# N32H7xx register map
Vendor: Nationstech Ltd.; File version: 1.0
CPU: CM7 r1p1, little endian, MPU, FPU, 4 interrupt priority bits
Registers are 32-bit, read-write, reset 0x0 unless marked. A register's access mark holds for its fields unless they carry their own. Offsets are from the block's base; [hi:lo] are bit positions; {n}, {i} and the like mark numbered series; 'fields as' and 'values as' point back to an identical list.

## SHRTIM1_TIMA — Super high resolution timer: TIMA
Base 0x400D8080
Same registers: SHRTIM2_TIMA 0x400D9080
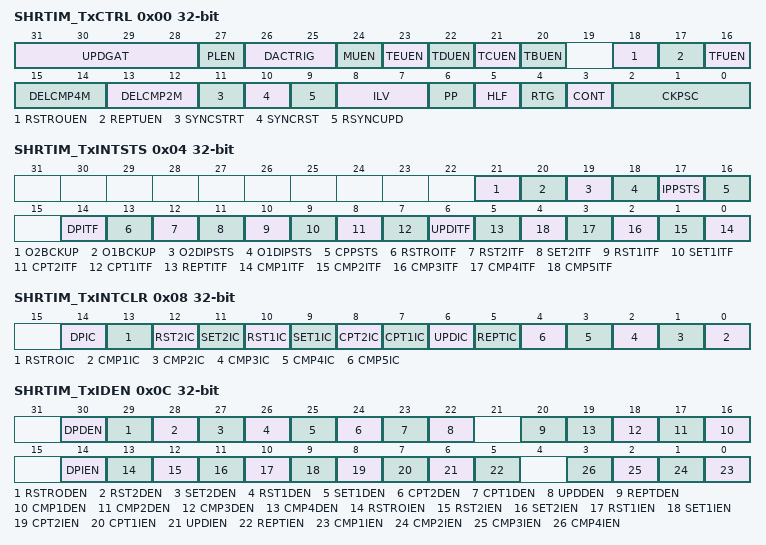
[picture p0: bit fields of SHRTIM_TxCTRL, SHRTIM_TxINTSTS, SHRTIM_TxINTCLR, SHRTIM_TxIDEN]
0x00 SHRTIM_TxCTRL — SHRTIM timer A control register
  [31:28] UPDGAT, [27] PLEN, [26:25] DACTRIG, [24] MUEN, [23] TEUEN, [22] TDUEN, [21] TCUEN, [20] TBUEN, [18] RSTROUEN, [17] REPTUEN, [16] TFUEN, [15:14] DELCMP4M, [13:12] DELCMP2M, [11] SYNCSTRT, [10] SYNCRST, [9] RSYNCUPD, [8:7] ILV, [6] PP, [5] HLF, [4] RTG, [3] CONT, [2:0] CKPSC
0x04 SHRTIM_TxINTSTS ro — SHRTIM timer A interrupt status register
  [21] O2BCKUP, [20] O1BCKUP, [19] O2DIPSTS, [18] O1DIPSTS, [17] IPPSTS, [16] CPPSTS, [14] DPITF, [13] RSTROITF, [12] RST2ITF, [11] SET2ITF, [10] RST1ITF, [9] SET1ITF, [8] CPT2ITF, [7] CPT1ITF, [6] UPDITF, [5] REPTITF, [n-1] CMP{n}ITF (n=1..5)
0x08 SHRTIM_TxINTCLR wo — SHRTIM timer x interrupt clear register
  [14] DPIC, [13] RSTROIC, [12] RST2IC, [11] SET2IC, [10] RST1IC, [9] SET1IC, [8] CPT2IC, [7] CPT1IC, [6] UPDIC, [5] REPTIC, [n-1] CMP{n}IC (n=1..5)
0x0C SHRTIM_TxIDEN — SHRTIM timer x interrupt DMA enable register
  [30] DPDEN, [29] RSTRODEN, [28] RST2DEN, [27] SET2DEN, [26] RST1DEN, [25] SET1DEN, [24] CPT2DEN, [23] CPT1DEN, [22] UPDDEN, [20] REPTDEN, [n+15] CMP{n}DEN (n=1..4), [14] DPIEN, [13] RSTROIEN, [12] RST2IEN, [11] SET2IEN, [10] RST1IEN, [9] SET1IEN, [8] CPT2IEN, [7] CPT1IEN, [6] UPDIEN, [5] REPTIEN, [n-1] CMP{n}IEN (n=1..4)
0x10 SHRTIM_TxCNT — SHRTIM timer x counter register
  [15:0] COUNT
0x14 SHRTIM_TxPRD reset 0xFFDF — SHRTIM timer x period register
  [15:0] PRD
0x18 SHRTIM_TxREPT — SHRTIM timer x repetition register
  [7:0] REPT
0x1C SHRTIM_TxCMP1DAT — SHRTIM timer x compare 1 register
  [15:0] CMP1DAT
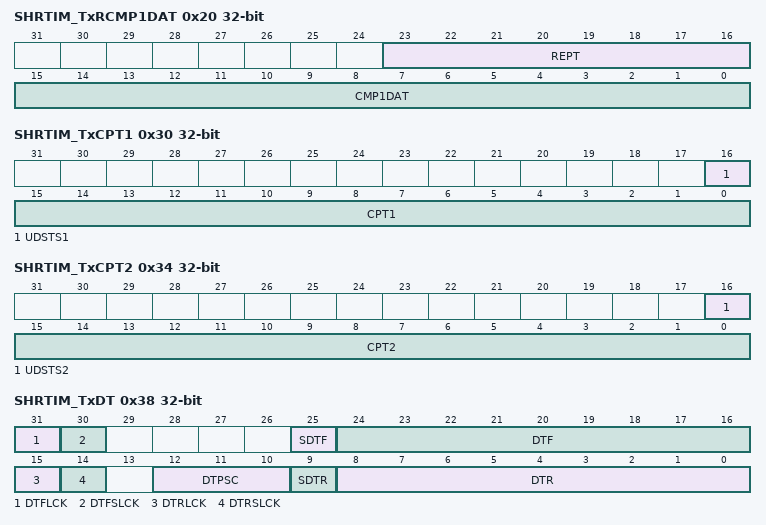
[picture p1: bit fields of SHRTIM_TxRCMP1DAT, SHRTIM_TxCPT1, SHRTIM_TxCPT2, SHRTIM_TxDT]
0x20 SHRTIM_TxRCMP1DAT — SHRTIM timer x compare 1 repetition alias register
  [23:16] REPT, [15:0] CMP1DAT
{0x1C+4i} SHRTIM_TxCMP{i}DAT (i=2..4) — SHRTIM timer x compare {i} register
  [15:0] CMP{i}DAT
0x30 SHRTIM_TxCPT1 — SHRTIM timer x compare 1 register
  [16] UDSTS1, [15:0] CPT1
0x34 SHRTIM_TxCPT2 — SHRTIM timer x compare 2 register
  [16] UDSTS2, [15:0] CPT2
0x38 SHRTIM_TxDT — SHRTIM timer x deadtime register
  [31] DTFLCK, [30] DTFSLCK, [25] SDTF, [24:16] DTF, [15] DTRLCK, [14] DTRSLCK, [12:10] DTPSC, [9] SDTR, [8:0] DTR
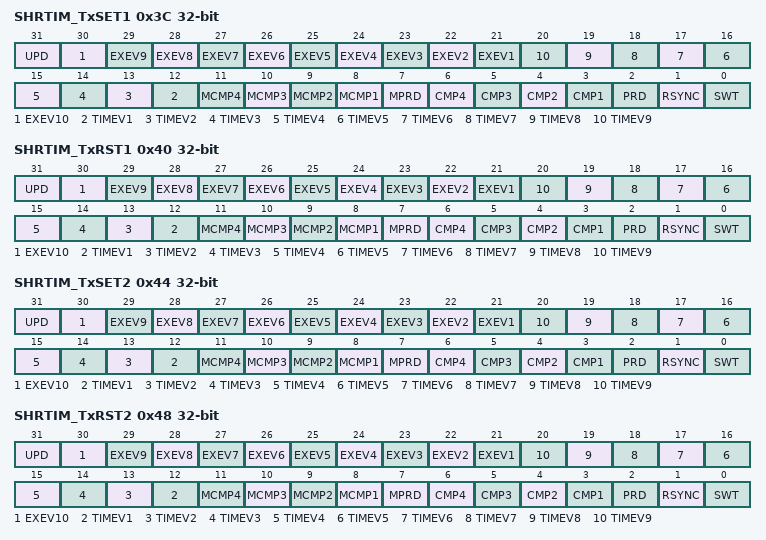
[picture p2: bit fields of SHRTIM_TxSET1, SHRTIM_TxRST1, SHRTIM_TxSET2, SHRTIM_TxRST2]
0x3C SHRTIM_TxSET1 — SHRTIM timer x set register 1
  [31] UPD, [n+20] EXEV{n} (n=1..10), [n+11] TIMEV{n} (n=1..9), [n+7] MCMP{n} (n=1..4), [7] MPRD, [n+2] CMP{n} (n=1..4), [2] PRD, [1] RSYNC, [0] SWT
0x40 SHRTIM_TxRST1 — SHRTIM timer x reset register 1
  fields as SHRTIM_TxSET1
0x44 SHRTIM_TxSET2 — SHRTIM timer x set register 2
  fields as SHRTIM_TxSET1
0x48 SHRTIM_TxRST2 — SHRTIM timer x reset register 2
  fields as SHRTIM_TxSET1
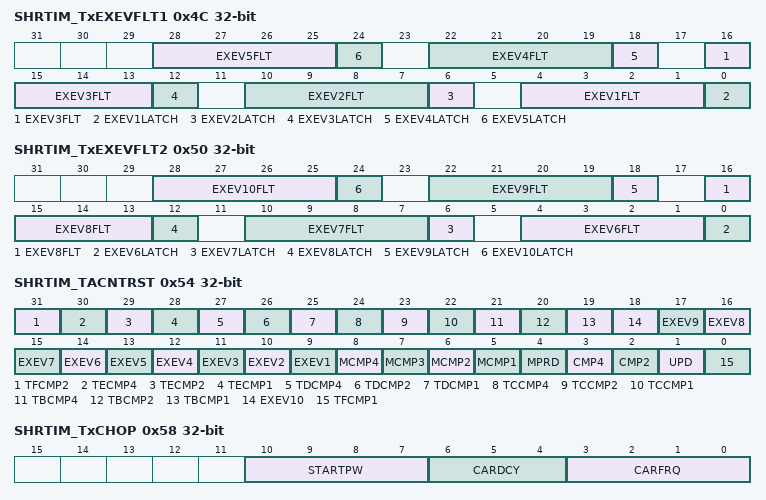
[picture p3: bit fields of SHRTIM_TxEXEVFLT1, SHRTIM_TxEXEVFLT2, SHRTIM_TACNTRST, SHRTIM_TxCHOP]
0x4C SHRTIM_TxEXEVFLT1 — SHRTIM timer x external event filtering register 1
  [6n-2:6n-5] EXEV{n}FLT (n=1..5), [6n-6] EXEV{n}LATCH (n=1..5)
0x50 SHRTIM_TxEXEVFLT2 — SHRTIM timer x external event filtering register 1
  [6n-32:6n-35] EXEV{n}FLT (n=6..10), [6n-36] EXEV{n}LATCH (n=6..10)
0x54 SHRTIM_TACNTRST — SHRTIM timer A reset
  [31] TFCMP2, [30] TECMP4, [29] TECMP2, [28] TECMP1, [27] TDCMP4, [26] TDCMP2, [25] TDCMP1, [24] TCCMP4, [23] TCCMP2, [22] TCCMP1, [21] TBCMP4, [20] TBCMP2, [19] TBCMP1, [n+8] EXEV{n} (n=1..10), [n+4] MCMP{n} (n=1..4), [4] MPRD, [3] CMP4, [2] CMP2, [1] UPD, [0] TFCMP1
0x58 SHRTIM_TxCHOP — SHRTIM timer x chopper register
  [10:7] STARTPW, [6:4] CARDCY, [3:0] CARFRQ
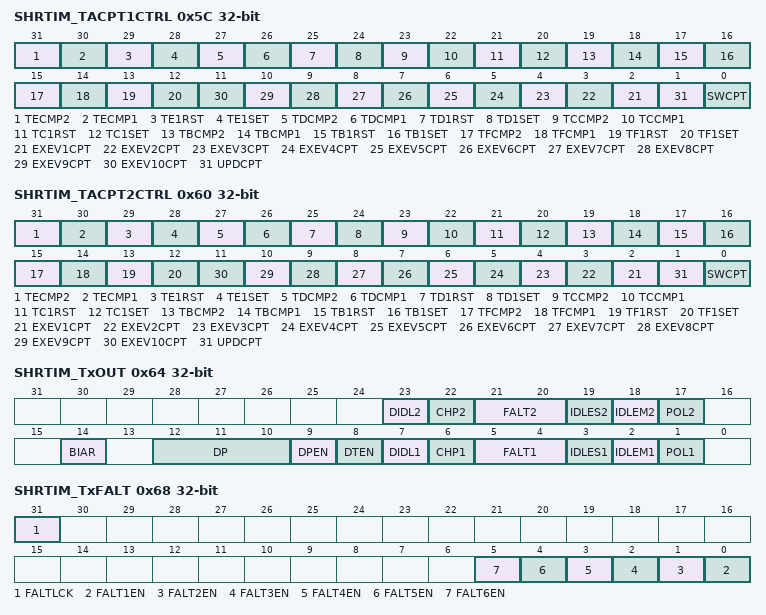
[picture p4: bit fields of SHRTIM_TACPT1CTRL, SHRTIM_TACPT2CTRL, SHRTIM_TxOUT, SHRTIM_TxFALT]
0x5C SHRTIM_TACPT1CTRL — SHRTIM timer A capture 1 control register
  [31] TECMP2, [30] TECMP1, [29] TE1RST, [28] TE1SET, [27] TDCMP2, [26] TDCMP1, [25] TD1RST, [24] TD1SET, [23] TCCMP2, [22] TCCMP1, [21] TC1RST, [20] TC1SET, [19] TBCMP2, [18] TBCMP1, [17] TB1RST, [16] TB1SET, [15] TFCMP2, [14] TFCMP1, [13] TF1RST, [12] TF1SET, [n+1] EXEV{n}CPT (n=1..10), [1] UPDCPT, [0] SWCPT
0x60 SHRTIM_TACPT2CTRL — SHRTIM timer A capture 2 control register
  fields as SHRTIM_TACPT1CTRL
0x64 SHRTIM_TxOUT — SHRTIM timer x output register
  [23] DIDL2, [22] CHP2, [21:20] FALT2, [19] IDLES2, [18] IDLEM2, [17] POL2, [14] BIAR, [12:10] DP, [9] DPEN, [8] DTEN, [7] DIDL1, [6] CHP1, [5:4] FALT1, [3] IDLES1, [2] IDLEM1, [1] POL1
0x68 SHRTIM_TxFALT — SHRTIM timer x fault register
  [31] FALTLCK, [n-1] FALT{n}EN (n=1..6)
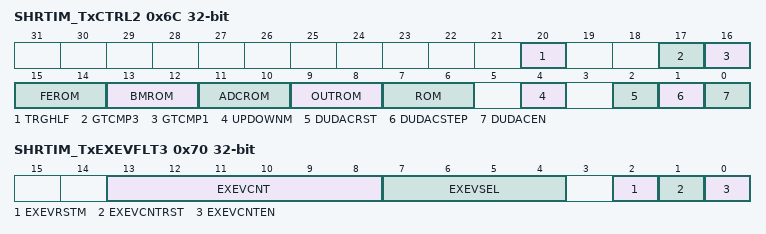
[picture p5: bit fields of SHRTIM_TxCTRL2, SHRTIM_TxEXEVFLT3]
0x6C SHRTIM_TxCTRL2 — SHRTIM timer x control register 2
  [20] TRGHLF, [17] GTCMP3, [16] GTCMP1, [15:14] FEROM, [13:12] BMROM, [11:10] ADCROM, [9:8] OUTROM, [7:6] ROM, [4] UPDOWNM, [2] DUDACRST, [1] DUDACSTEP, [0] DUDACEN
0x70 SHRTIM_TxEXEVFLT3 — SHRTIM timer x external event filter register
  [13:8] EXEVCNT, [7:4] EXEVSEL, [2] EXEVRSTM, [1] EXEVCNTRST, [0] EXEVCNTEN
0x74 SHRTIM_TxCMP5DAT — SHRTIM timer x compare 5 register
  [15:0] CMP5DAT

## SHRTIM1_TIMB — Super high resolution timer: TIMB
Base 0x400D8100
Same registers: SHRTIM2_TIMB 0x400D9100
Registers as SHRTIM1_TIMA, without SHRTIM_TACNTRST, SHRTIM_TACPT1CTRL, SHRTIM_TACPT2CTRL; these are added or differ:
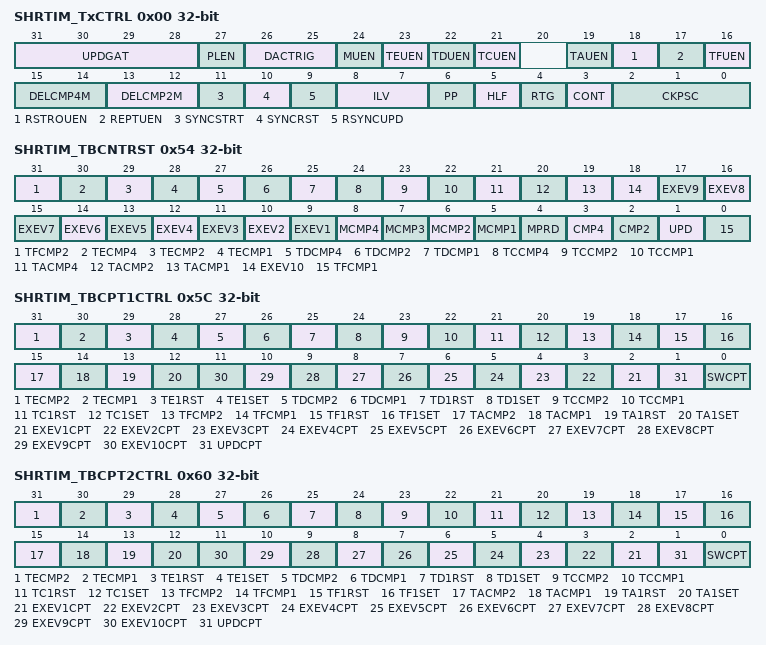
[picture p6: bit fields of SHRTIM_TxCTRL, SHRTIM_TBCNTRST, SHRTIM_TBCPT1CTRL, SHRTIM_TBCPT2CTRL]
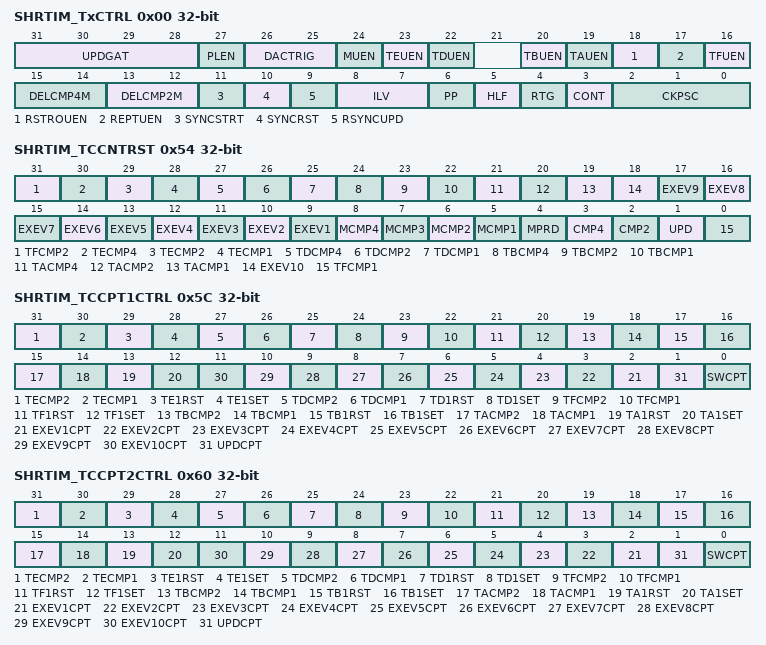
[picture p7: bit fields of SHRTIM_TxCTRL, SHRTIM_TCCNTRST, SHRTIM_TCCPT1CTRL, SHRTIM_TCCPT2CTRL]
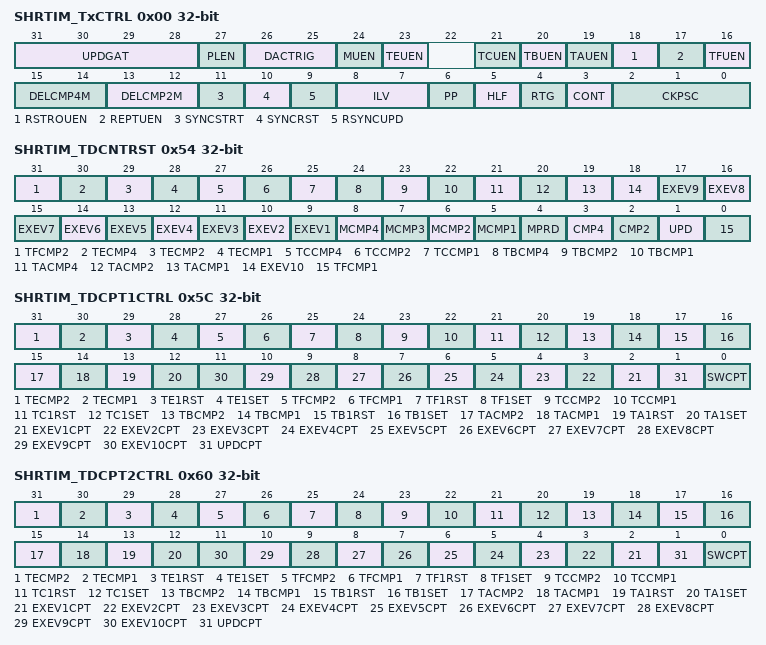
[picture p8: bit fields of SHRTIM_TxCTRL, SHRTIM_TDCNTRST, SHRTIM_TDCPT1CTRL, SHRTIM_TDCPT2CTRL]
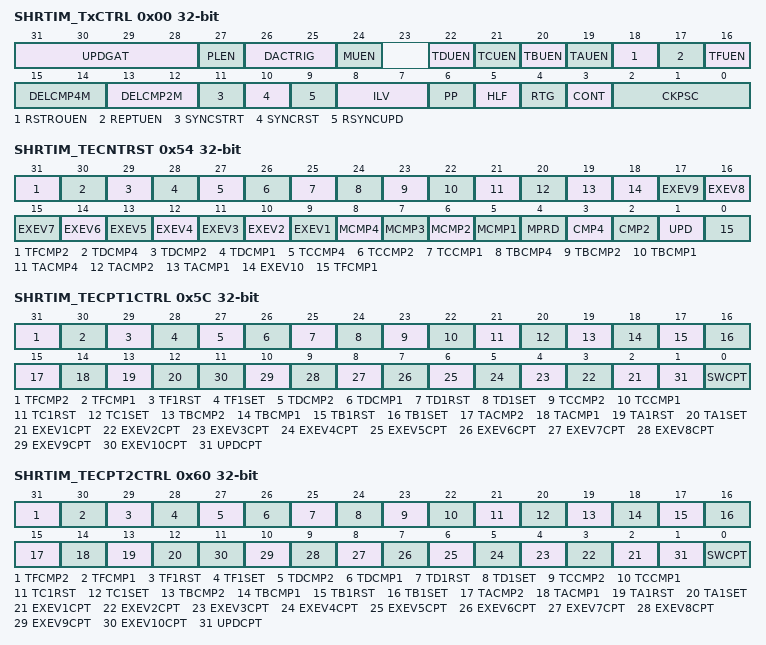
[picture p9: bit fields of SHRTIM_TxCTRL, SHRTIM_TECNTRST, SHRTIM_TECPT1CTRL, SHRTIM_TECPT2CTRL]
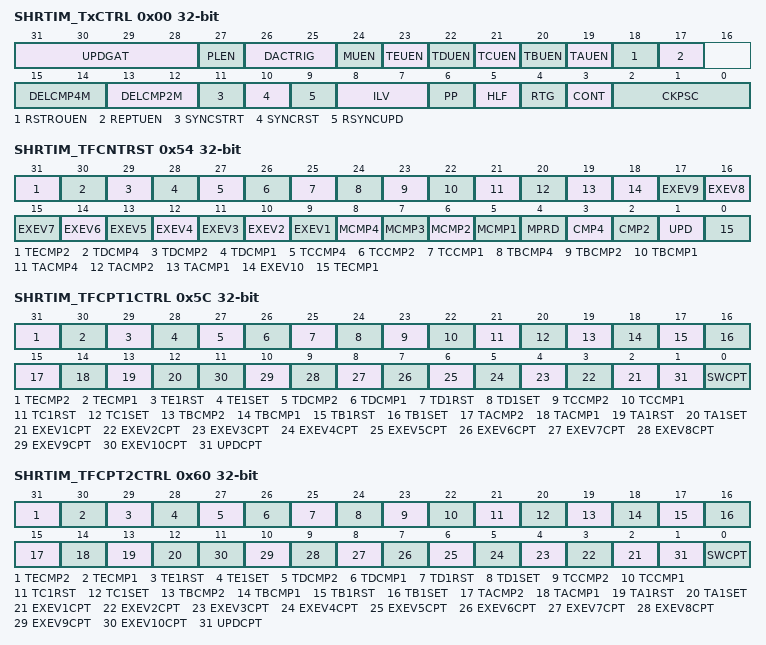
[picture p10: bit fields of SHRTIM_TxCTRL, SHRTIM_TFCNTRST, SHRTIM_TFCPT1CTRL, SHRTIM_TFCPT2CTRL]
0x00 SHRTIM_TxCTRL — SHRTIM timer A control register
  [31:28] UPDGAT, [27] PLEN, [26:25] DACTRIG, [24] MUEN, [23] TEUEN, [22] TDUEN, [21] TCUEN, [19] TAUEN, [18] RSTROUEN, [17] REPTUEN, [16] TFUEN, [15:14] DELCMP4M, [13:12] DELCMP2M, [11] SYNCSTRT, [10] SYNCRST, [9] RSYNCUPD, [8:7] ILV, [6] PP, [5] HLF, [4] RTG, [3] CONT, [2:0] CKPSC
0x54 SHRTIM_TBCNTRST — SHRTIM timer B reset
  [31] TFCMP2, [30] TECMP4, [29] TECMP2, [28] TECMP1, [27] TDCMP4, [26] TDCMP2, [25] TDCMP1, [24] TCCMP4, [23] TCCMP2, [22] TCCMP1, [21] TACMP4, [20] TACMP2, [19] TACMP1, [n+8] EXEV{n} (n=1..10), [n+4] MCMP{n} (n=1..4), [4] MPRD, [3] CMP4, [2] CMP2, [1] UPD, [0] TFCMP1
0x5C SHRTIM_TBCPT1CTRL — SHRTIM timer B capture 1 control register
  [31] TECMP2, [30] TECMP1, [29] TE1RST, [28] TE1SET, [27] TDCMP2, [26] TDCMP1, [25] TD1RST, [24] TD1SET, [23] TCCMP2, [22] TCCMP1, [21] TC1RST, [20] TC1SET, [19] TFCMP2, [18] TFCMP1, [17] TF1RST, [16] TF1SET, [15] TACMP2, [14] TACMP1, [13] TA1RST, [12] TA1SET, [n+1] EXEV{n}CPT (n=1..10), [1] UPDCPT, [0] SWCPT
0x60 SHRTIM_TBCPT2CTRL — SHRTIM timer B capture 2 control register
  fields as SHRTIM_TBCPT1CTRL

## SHRTIM1_TIMC — Super high resolution timer: TIMC
Base 0x400D8180
Same registers: SHRTIM2_TIMC 0x400D9180
Registers as SHRTIM1_TIMA, without SHRTIM_TACNTRST, SHRTIM_TACPT1CTRL, SHRTIM_TACPT2CTRL; these are added or differ:
0x00 SHRTIM_TxCTRL — SHRTIM timer A control register
  [31:28] UPDGAT, [27] PLEN, [26:25] DACTRIG, [24] MUEN, [23] TEUEN, [22] TDUEN, [20] TBUEN, [19] TAUEN, [18] RSTROUEN, [17] REPTUEN, [16] TFUEN, [15:14] DELCMP4M, [13:12] DELCMP2M, [11] SYNCSTRT, [10] SYNCRST, [9] RSYNCUPD, [8:7] ILV, [6] PP, [5] HLF, [4] RTG, [3] CONT, [2:0] CKPSC
0x54 SHRTIM_TCCNTRST — SHRTIM timer C reset
  [31] TFCMP2, [30] TECMP4, [29] TECMP2, [28] TECMP1, [27] TDCMP4, [26] TDCMP2, [25] TDCMP1, [24] TBCMP4, [23] TBCMP2, [22] TBCMP1, [21] TACMP4, [20] TACMP2, [19] TACMP1, [n+8] EXEV{n} (n=1..10), [n+4] MCMP{n} (n=1..4), [4] MPRD, [3] CMP4, [2] CMP2, [1] UPD, [0] TFCMP1
0x5C SHRTIM_TCCPT1CTRL — SHRTIM timer C capture 1 control register
  [31] TECMP2, [30] TECMP1, [29] TE1RST, [28] TE1SET, [27] TDCMP2, [26] TDCMP1, [25] TD1RST, [24] TD1SET, [23] TFCMP2, [22] TFCMP1, [21] TF1RST, [20] TF1SET, [19] TBCMP2, [18] TBCMP1, [17] TB1RST, [16] TB1SET, [15] TACMP2, [14] TACMP1, [13] TA1RST, [12] TA1SET, [n+1] EXEV{n}CPT (n=1..10), [1] UPDCPT, [0] SWCPT
0x60 SHRTIM_TCCPT2CTRL — SHRTIM timer C capture 2 control register
  fields as SHRTIM_TCCPT1CTRL

## SHRTIM1_TIMD — Super high resolution timer: TIMD
Base 0x400D8200
Same registers: SHRTIM2_TIMD 0x400D9200
Registers as SHRTIM1_TIMA, without SHRTIM_TACNTRST, SHRTIM_TACPT1CTRL, SHRTIM_TACPT2CTRL; these are added or differ:
0x00 SHRTIM_TxCTRL — SHRTIM timer A control register
  [31:28] UPDGAT, [27] PLEN, [26:25] DACTRIG, [24] MUEN, [23] TEUEN, [21] TCUEN, [20] TBUEN, [19] TAUEN, [18] RSTROUEN, [17] REPTUEN, [16] TFUEN, [15:14] DELCMP4M, [13:12] DELCMP2M, [11] SYNCSTRT, [10] SYNCRST, [9] RSYNCUPD, [8:7] ILV, [6] PP, [5] HLF, [4] RTG, [3] CONT, [2:0] CKPSC
0x54 SHRTIM_TDCNTRST — SHRTIM timer D reset
  [31] TFCMP2, [30] TECMP4, [29] TECMP2, [28] TECMP1, [27] TCCMP4, [26] TCCMP2, [25] TCCMP1, [24] TBCMP4, [23] TBCMP2, [22] TBCMP1, [21] TACMP4, [20] TACMP2, [19] TACMP1, [n+8] EXEV{n} (n=1..10), [n+4] MCMP{n} (n=1..4), [4] MPRD, [3] CMP4, [2] CMP2, [1] UPD, [0] TFCMP1
0x5C SHRTIM_TDCPT1CTRL — SHRTIM timer D capture 1 control register
  [31] TECMP2, [30] TECMP1, [29] TE1RST, [28] TE1SET, [27] TFCMP2, [26] TFCMP1, [25] TF1RST, [24] TF1SET, [23] TCCMP2, [22] TCCMP1, [21] TC1RST, [20] TC1SET, [19] TBCMP2, [18] TBCMP1, [17] TB1RST, [16] TB1SET, [15] TACMP2, [14] TACMP1, [13] TA1RST, [12] TA1SET, [n+1] EXEV{n}CPT (n=1..10), [1] UPDCPT, [0] SWCPT
0x60 SHRTIM_TDCPT2CTRL — SHRTIM timer D capture 2 control register
  fields as SHRTIM_TDCPT1CTRL

## SHRTIM1_TIME — Super high resolution timer: TIME
Base 0x400D8280
Same registers: SHRTIM2_TIME 0x400D9280
Registers as SHRTIM1_TIMA, without SHRTIM_TACNTRST, SHRTIM_TACPT1CTRL, SHRTIM_TACPT2CTRL; these are added or differ:
0x00 SHRTIM_TxCTRL — SHRTIM timer A control register
  [31:28] UPDGAT, [27] PLEN, [26:25] DACTRIG, [24] MUEN, [22] TDUEN, [21] TCUEN, [20] TBUEN, [19] TAUEN, [18] RSTROUEN, [17] REPTUEN, [16] TFUEN, [15:14] DELCMP4M, [13:12] DELCMP2M, [11] SYNCSTRT, [10] SYNCRST, [9] RSYNCUPD, [8:7] ILV, [6] PP, [5] HLF, [4] RTG, [3] CONT, [2:0] CKPSC
0x54 SHRTIM_TECNTRST — SHRTIM timer E reset
  [31] TFCMP2, [30] TDCMP4, [29] TDCMP2, [28] TDCMP1, [27] TCCMP4, [26] TCCMP2, [25] TCCMP1, [24] TBCMP4, [23] TBCMP2, [22] TBCMP1, [21] TACMP4, [20] TACMP2, [19] TACMP1, [n+8] EXEV{n} (n=1..10), [n+4] MCMP{n} (n=1..4), [4] MPRD, [3] CMP4, [2] CMP2, [1] UPD, [0] TFCMP1
0x5C SHRTIM_TECPT1CTRL — SHRTIM timer E capture 1 control register
  [31] TFCMP2, [30] TFCMP1, [29] TF1RST, [28] TF1SET, [27] TDCMP2, [26] TDCMP1, [25] TD1RST, [24] TD1SET, [23] TCCMP2, [22] TCCMP1, [21] TC1RST, [20] TC1SET, [19] TBCMP2, [18] TBCMP1, [17] TB1RST, [16] TB1SET, [15] TACMP2, [14] TACMP1, [13] TA1RST, [12] TA1SET, [n+1] EXEV{n}CPT (n=1..10), [1] UPDCPT, [0] SWCPT
0x60 SHRTIM_TECPT2CTRL — SHRTIM timer E capture 2 control register
  fields as SHRTIM_TECPT1CTRL

## SHRTIM1_TIMF — Super high resolution timer: TIMF
Base 0x400D8300
Same registers: SHRTIM2_TIMF 0x400D9300
Registers as SHRTIM1_TIMA, without SHRTIM_TACNTRST, SHRTIM_TACPT1CTRL, SHRTIM_TACPT2CTRL; these are added or differ:
0x00 SHRTIM_TxCTRL — SHRTIM timer A control register
  [31:28] UPDGAT, [27] PLEN, [26:25] DACTRIG, [24] MUEN, [23] TEUEN, [22] TDUEN, [21] TCUEN, [20] TBUEN, [19] TAUEN, [18] RSTROUEN, [17] REPTUEN, [15:14] DELCMP4M, [13:12] DELCMP2M, [11] SYNCSTRT, [10] SYNCRST, [9] RSYNCUPD, [8:7] ILV, [6] PP, [5] HLF, [4] RTG, [3] CONT, [2:0] CKPSC
0x54 SHRTIM_TFCNTRST — SHRTIM timer F reset
  [31] TECMP2, [30] TDCMP4, [29] TDCMP2, [28] TDCMP1, [27] TCCMP4, [26] TCCMP2, [25] TCCMP1, [24] TBCMP4, [23] TBCMP2, [22] TBCMP1, [21] TACMP4, [20] TACMP2, [19] TACMP1, [n+8] EXEV{n} (n=1..10), [n+4] MCMP{n} (n=1..4), [4] MPRD, [3] CMP4, [2] CMP2, [1] UPD, [0] TECMP1
0x5C SHRTIM_TFCPT1CTRL — SHRTIM timer F capture 1 control register
  [31] TECMP2, [30] TECMP1, [29] TE1RST, [28] TE1SET, [27] TDCMP2, [26] TDCMP1, [25] TD1RST, [24] TD1SET, [23] TCCMP2, [22] TCCMP1, [21] TC1RST, [20] TC1SET, [19] TBCMP2, [18] TBCMP1, [17] TB1RST, [16] TB1SET, [15] TACMP2, [14] TACMP1, [13] TA1RST, [12] TA1SET, [n+1] EXEV{n}CPT (n=1..10), [1] UPDCPT, [0] SWCPT
0x60 SHRTIM_TFCPT2CTRL — SHRTIM timer F capture 2 control register
  fields as SHRTIM_TFCPT1CTRL
